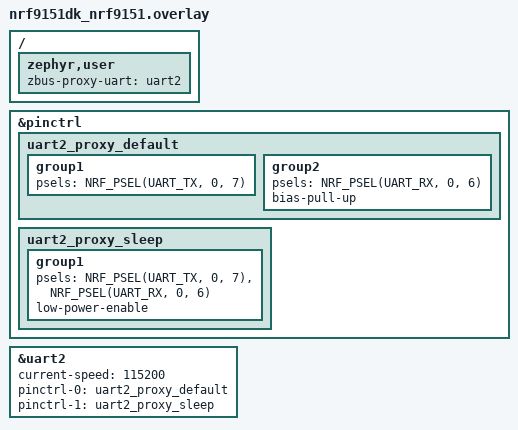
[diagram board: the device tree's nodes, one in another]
/*
 * Copyright (c) 2026 Nordic Semiconductor ASA
 *
 * SPDX-License-Identifier: Apache-2.0
 */

/ {
	zephyr,user {
		zbus-proxy-uart = <&uart2>;
	};
};

&pinctrl {
	uart2_proxy_default: uart2_proxy_default {
		group1 {
			psels = <NRF_PSEL(UART_TX, 0, 7)>;
		};

		group2 {
			psels = <NRF_PSEL(UART_RX, 0, 6)>;
			bias-pull-up;
		};
	};

	uart2_proxy_sleep: uart2_proxy_sleep {
		group1 {
			psels = <NRF_PSEL(UART_TX, 0, 7)>,
				<NRF_PSEL(UART_RX, 0, 6)>;
			low-power-enable;
		};
	};
};

&uart2 {
	status = "okay";
	current-speed = <115200>;
	/delete-property/ hw-flow-control;
	pinctrl-0 = <&uart2_proxy_default>;
	pinctrl-1 = <&uart2_proxy_sleep>;
	pinctrl-names = "default", "sleep";
};
